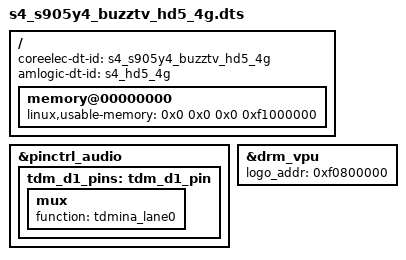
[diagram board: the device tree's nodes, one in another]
#include "s4_s905y4_buzztv_hd5_2g.dts"

/ {
	coreelec-dt-id = "s4_s905y4_buzztv_hd5_4g";
	amlogic-dt-id = "s4_hd5_4g";

	memory@00000000 {
		linux,usable-memory = <0x0 0x0 0x0 0xf1000000>;
	};
};

&pinctrl_audio {
	tdm_d1_pins: tdm_d1_pin {
		mux {
			function = "tdmina_lane0";
		};
	};
};

&drm_vpu {
	logo_addr = "0xf0800000";
};
